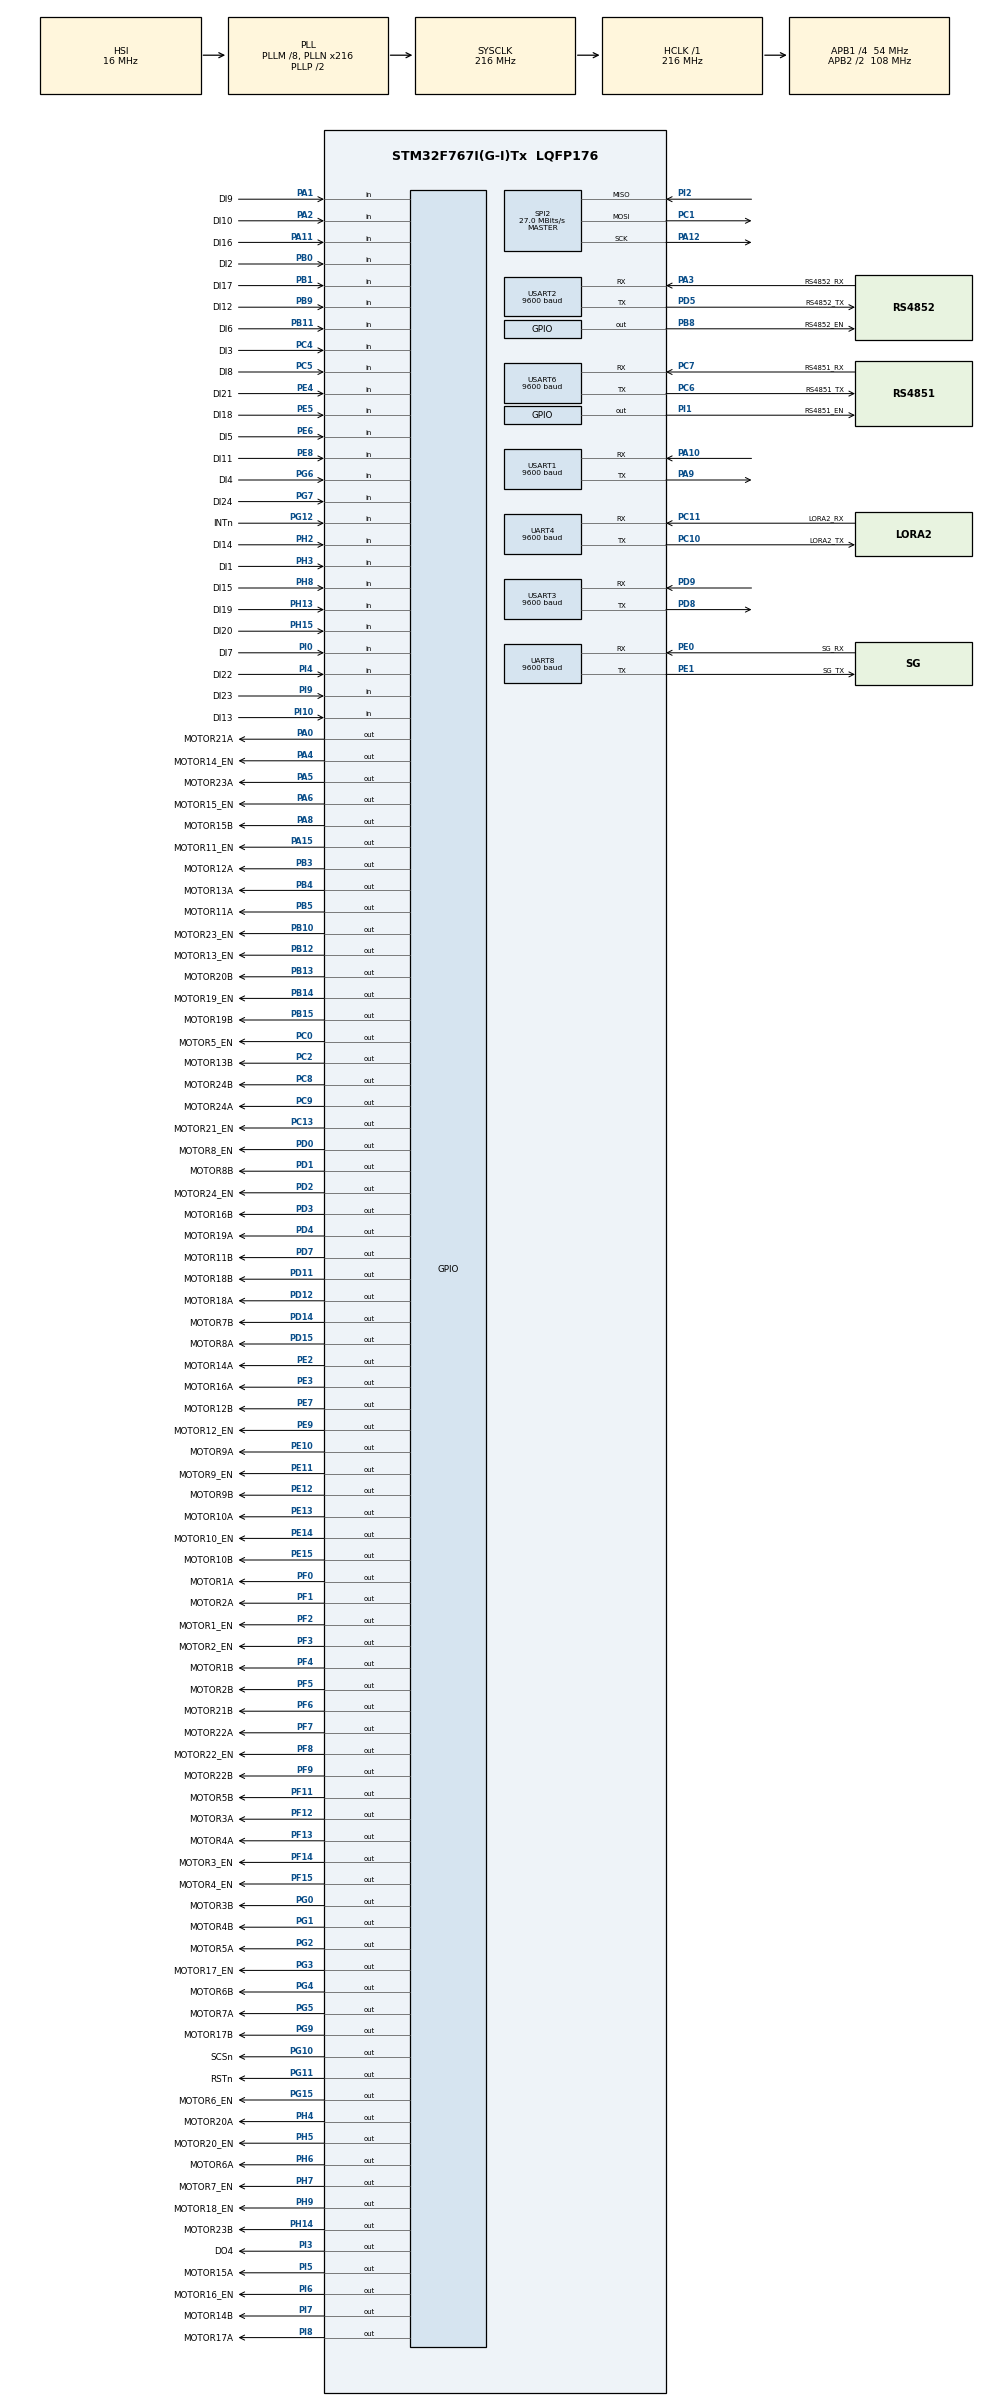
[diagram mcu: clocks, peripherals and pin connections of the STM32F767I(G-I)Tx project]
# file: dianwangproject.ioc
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Dma.Request0=USART6_RX
Dma.Request1=USART6_TX
Dma.Request10=USART3_TX
Dma.Request2=USART1_RX
Dma.Request3=USART1_TX
Dma.Request4=USART2_RX
Dma.Request5=USART2_TX
Dma.Request6=UART4_RX
Dma.Request7=UART4_TX
Dma.Request8=UART8_TX
Dma.Request9=USART3_RX
Dma.UART4_RX.6.Direction=DMA_PERIPH_TO_MEMORY
Dma.UART4_RX.6.FIFOMode=DMA_FIFOMODE_DISABLE
Dma.UART4_RX.6.Instance=DMA1_Stream2
Dma.UART4_RX.6.MemDataAlignment=DMA_MDATAALIGN_BYTE
Dma.UART4_RX.6.MemInc=DMA_MINC_ENABLE
Dma.UART4_RX.6.Mode=DMA_NORMAL
Dma.UART4_RX.6.PeriphDataAlignment=DMA_PDATAALIGN_BYTE
Dma.UART4_RX.6.PeriphInc=DMA_PINC_DISABLE
Dma.UART4_RX.6.Priority=DMA_PRIORITY_LOW
Dma.UART4_TX.7.Direction=DMA_MEMORY_TO_PERIPH
Dma.UART4_TX.7.FIFOMode=DMA_FIFOMODE_DISABLE
Dma.UART4_TX.7.Instance=DMA1_Stream4
Dma.UART4_TX.7.MemDataAlignment=DMA_MDATAALIGN_BYTE
Dma.UART4_TX.7.MemInc=DMA_MINC_ENABLE
Dma.UART4_TX.7.Mode=DMA_NORMAL
Dma.UART4_TX.7.PeriphDataAlignment=DMA_PDATAALIGN_BYTE
Dma.UART4_TX.7.PeriphInc=DMA_PINC_DISABLE
Dma.UART4_TX.7.Priority=DMA_PRIORITY_LOW
Dma.UART8_TX.8.Direction=DMA_MEMORY_TO_PERIPH
Dma.UART8_TX.8.FIFOMode=DMA_FIFOMODE_DISABLE
Dma.UART8_TX.8.Instance=DMA1_Stream0
Dma.UART8_TX.8.MemDataAlignment=DMA_MDATAALIGN_BYTE
Dma.UART8_TX.8.MemInc=DMA_MINC_ENABLE
Dma.UART8_TX.8.Mode=DMA_NORMAL
Dma.UART8_TX.8.PeriphDataAlignment=DMA_PDATAALIGN_BYTE
Dma.UART8_TX.8.PeriphInc=DMA_PINC_DISABLE
Dma.UART8_TX.8.Priority=DMA_PRIORITY_LOW
Dma.USART1_RX.2.Direction=DMA_PERIPH_TO_MEMORY
Dma.USART1_RX.2.FIFOMode=DMA_FIFOMODE_DISABLE
Dma.USART1_RX.2.Instance=DMA2_Stream2
Dma.USART1_RX.2.MemDataAlignment=DMA_MDATAALIGN_BYTE
Dma.USART1_RX.2.MemInc=DMA_MINC_ENABLE
Dma.USART1_RX.2.Mode=DMA_NORMAL
Dma.USART1_RX.2.PeriphDataAlignment=DMA_PDATAALIGN_BYTE
Dma.USART1_RX.2.PeriphInc=DMA_PINC_DISABLE
Dma.USART1_RX.2.Priority=DMA_PRIORITY_LOW
Dma.USART1_TX.3.Direction=DMA_MEMORY_TO_PERIPH
Dma.USART1_TX.3.FIFOMode=DMA_FIFOMODE_DISABLE
Dma.USART1_TX.3.Instance=DMA2_Stream7
Dma.USART1_TX.3.MemDataAlignment=DMA_MDATAALIGN_BYTE
Dma.USART1_TX.3.MemInc=DMA_MINC_ENABLE
Dma.USART1_TX.3.Mode=DMA_NORMAL
Dma.USART1_TX.3.PeriphDataAlignment=DMA_PDATAALIGN_BYTE
Dma.USART1_TX.3.PeriphInc=DMA_PINC_DISABLE
Dma.USART1_TX.3.Priority=DMA_PRIORITY_LOW
Dma.USART2_RX.4.Direction=DMA_PERIPH_TO_MEMORY
Dma.USART2_RX.4.FIFOMode=DMA_FIFOMODE_DISABLE
Dma.USART2_RX.4.Instance=DMA1_Stream5
Dma.USART2_RX.4.MemDataAlignment=DMA_MDATAALIGN_BYTE
Dma.USART2_RX.4.MemInc=DMA_MINC_ENABLE
Dma.USART2_RX.4.Mode=DMA_NORMAL
Dma.USART2_RX.4.PeriphDataAlignment=DMA_PDATAALIGN_BYTE
Dma.USART2_RX.4.PeriphInc=DMA_PINC_DISABLE
Dma.USART2_RX.4.Priority=DMA_PRIORITY_LOW
Dma.USART2_TX.5.Direction=DMA_MEMORY_TO_PERIPH
Dma.USART2_TX.5.FIFOMode=DMA_FIFOMODE_DISABLE
Dma.USART2_TX.5.Instance=DMA1_Stream6
Dma.USART2_TX.5.MemDataAlignment=DMA_MDATAALIGN_BYTE
Dma.USART2_TX.5.MemInc=DMA_MINC_ENABLE
Dma.USART2_TX.5.Mode=DMA_NORMAL
Dma.USART2_TX.5.PeriphDataAlignment=DMA_PDATAALIGN_BYTE
Dma.USART2_TX.5.PeriphInc=DMA_PINC_DISABLE
Dma.USART2_TX.5.Priority=DMA_PRIORITY_LOW
Dma.USART3_RX.9.Direction=DMA_PERIPH_TO_MEMORY
Dma.USART3_RX.9.FIFOMode=DMA_FIFOMODE_DISABLE
Dma.USART3_RX.9.Instance=DMA1_Stream1
Dma.USART3_RX.9.MemDataAlignment=DMA_MDATAALIGN_BYTE
Dma.USART3_RX.9.MemInc=DMA_MINC_ENABLE
Dma.USART3_RX.9.Mode=DMA_NORMAL
Dma.USART3_RX.9.PeriphDataAlignment=DMA_PDATAALIGN_BYTE
Dma.USART3_RX.9.PeriphInc=DMA_PINC_DISABLE
Dma.USART3_RX.9.Priority=DMA_PRIORITY_LOW
Dma.USART3_TX.10.Direction=DMA_MEMORY_TO_PERIPH
Dma.USART3_TX.10.FIFOMode=DMA_FIFOMODE_DISABLE
Dma.USART3_TX.10.Instance=DMA1_Stream3
Dma.USART3_TX.10.MemDataAlignment=DMA_MDATAALIGN_BYTE
Dma.USART3_TX.10.MemInc=DMA_MINC_ENABLE
Dma.USART3_TX.10.Mode=DMA_NORMAL
Dma.USART3_TX.10.PeriphDataAlignment=DMA_PDATAALIGN_BYTE
Dma.USART3_TX.10.PeriphInc=DMA_PINC_DISABLE
Dma.USART3_TX.10.Priority=DMA_PRIORITY_LOW
Dma.USART6_RX.0.Direction=DMA_PERIPH_TO_MEMORY
Dma.USART6_RX.0.FIFOMode=DMA_FIFOMODE_DISABLE
Dma.USART6_RX.0.Instance=DMA2_Stream1
Dma.USART6_RX.0.MemDataAlignment=DMA_MDATAALIGN_BYTE
Dma.USART6_RX.0.MemInc=DMA_MINC_ENABLE
Dma.USART6_RX.0.Mode=DMA_NORMAL
Dma.USART6_RX.0.PeriphDataAlignment=DMA_PDATAALIGN_BYTE
Dma.USART6_RX.0.PeriphInc=DMA_PINC_DISABLE
Dma.USART6_RX.0.Priority=DMA_PRIORITY_VERY_HIGH
Dma.USART6_TX.1.Direction=DMA_MEMORY_TO_PERIPH
Dma.USART6_TX.1.FIFOMode=DMA_FIFOMODE_DISABLE
Dma.USART6_TX.1.Instance=DMA2_Stream6
Dma.USART6_TX.1.MemDataAlignment=DMA_MDATAALIGN_BYTE
Dma.USART6_TX.1.MemInc=DMA_MINC_ENABLE
Dma.USART6_TX.1.Mode=DMA_NORMAL
Dma.USART6_TX.1.PeriphDataAlignment=DMA_PDATAALIGN_BYTE
Dma.USART6_TX.1.PeriphInc=DMA_PINC_DISABLE
Dma.USART6_TX.1.Priority=DMA_PRIORITY_VERY_HIGH
Mcu.Family=STM32F7
Mcu.Name=STM32F767I(G-I)Tx
Mcu.Package=LQFP176
NVIC.DMA1_Stream0_IRQn=true\:0\:0\:false\:false\:true\:false\:true\:true
NVIC.DMA1_Stream1_IRQn=true\:0\:0\:false\:false\:true\:false\:true\:true
NVIC.DMA1_Stream2_IRQn=true\:0\:0\:false\:false\:true\:false\:true\:true
NVIC.DMA1_Stream3_IRQn=true\:0\:0\:false\:false\:true\:false\:true\:true
NVIC.DMA1_Stream4_IRQn=true\:0\:0\:false\:false\:true\:false\:true\:true
NVIC.DMA1_Stream5_IRQn=true\:0\:0\:false\:false\:true\:false\:true\:true
NVIC.DMA1_Stream6_IRQn=true\:0\:0\:false\:false\:true\:false\:true\:true
NVIC.DMA2_Stream1_IRQn=true\:0\:0\:false\:false\:true\:false\:true\:true
NVIC.DMA2_Stream2_IRQn=true\:0\:0\:false\:false\:true\:false\:true\:true
NVIC.DMA2_Stream6_IRQn=true\:0\:0\:false\:false\:true\:false\:true\:true
NVIC.DMA2_Stream7_IRQn=true\:0\:0\:false\:false\:true\:false\:true\:true
NVIC.PriorityGroup=NVIC_PRIORITYGROUP_4
NVIC.TIM2_IRQn=true\:0\:0\:false\:false\:true\:true\:true\:true
NVIC.TIM3_IRQn=true\:0\:0\:false\:false\:true\:true\:true\:true
NVIC.UART4_IRQn=true\:0\:0\:false\:false\:true\:true\:true\:true
NVIC.UART8_IRQn=true\:0\:0\:false\:false\:true\:true\:true\:true
NVIC.USART1_IRQn=true\:0\:0\:false\:false\:true\:true\:true\:true
NVIC.USART2_IRQn=true\:0\:0\:false\:false\:true\:true\:true\:true
NVIC.USART3_IRQn=true\:0\:0\:false\:false\:true\:true\:true\:true
NVIC.USART6_IRQn=true\:0\:0\:false\:false\:true\:true\:true\:true
PA0/WKUP.GPIO_Label=MOTOR21A
PA0/WKUP.GPIO_Speed=GPIO_SPEED_FREQ_HIGH
PA0/WKUP.Signal=GPIO_Output
PA1.GPIO_Label=DI9
PA1.GPIO_PuPd=GPIO_PULLUP
PA1.Signal=GPIO_Input
PA10.Mode=Asynchronous
PA10.Signal=USART1_RX
PA11.GPIO_Label=DI16
PA11.GPIO_PuPd=GPIO_PULLUP
PA11.Signal=GPIO_Input
PA12.Mode=Full_Duplex_Master
PA12.Signal=SPI2_SCK
PA13.Mode=Serial_Wire
PA13.Signal=SYS_JTMS-SWDIO
PA14.Mode=Serial_Wire
PA14.Signal=SYS_JTCK-SWCLK
PA15.GPIO_Label=MOTOR11_EN
PA15.GPIO_Speed=GPIO_SPEED_FREQ_HIGH
PA15.PinState=GPIO_PIN_SET
PA15.Signal=GPIO_Output
PA2.GPIO_Label=DI10
PA2.GPIO_PuPd=GPIO_PULLUP
PA2.Signal=GPIO_Input
PA3.GPIO_Label=RS4852_RX
PA3.Mode=Asynchronous
PA3.Signal=USART2_RX
PA4.GPIO_Label=MOTOR14_EN
PA4.GPIO_Speed=GPIO_SPEED_FREQ_HIGH
PA4.Signal=GPIO_Output
PA5.GPIO_Label=MOTOR23A
PA5.GPIO_Speed=GPIO_SPEED_FREQ_HIGH
PA5.Signal=GPIO_Output
PA6.GPIO_Label=MOTOR15_EN
PA6.GPIO_Speed=GPIO_SPEED_FREQ_HIGH
PA6.Signal=GPIO_Output
PA8.GPIO_Label=MOTOR15B
PA8.GPIO_Speed=GPIO_SPEED_FREQ_HIGH
PA8.Signal=GPIO_Output
PA9.Mode=Asynchronous
PA9.Signal=USART1_TX
PB0.GPIO_Label=DI2
PB0.GPIO_PuPd=GPIO_PULLUP
PB0.Signal=GPIO_Input
PB1.GPIO_Label=DI17
PB1.GPIO_PuPd=GPIO_PULLUP
PB1.Signal=GPIO_Input
PB10.GPIO_Label=MOTOR23_EN
PB10.GPIO_Speed=GPIO_SPEED_FREQ_HIGH
PB10.Signal=GPIO_Output
PB11.GPIO_Label=DI6
PB11.GPIO_PuPd=GPIO_PULLUP
PB11.Signal=GPIO_Input
PB12.GPIO_Label=MOTOR13_EN
PB12.GPIO_Speed=GPIO_SPEED_FREQ_HIGH
PB12.Signal=GPIO_Output
PB13.GPIO_Label=MOTOR20B
PB13.GPIO_Speed=GPIO_SPEED_FREQ_HIGH
PB13.Signal=GPIO_Output
PB14.GPIO_Label=MOTOR19_EN
PB14.GPIO_Speed=GPIO_SPEED_FREQ_HIGH
PB14.Signal=GPIO_Output
PB15.GPIO_Label=MOTOR19B
PB15.GPIO_Speed=GPIO_SPEED_FREQ_HIGH
PB15.Signal=GPIO_Output
PB3.GPIO_Label=MOTOR12A
PB3.GPIO_Speed=GPIO_SPEED_FREQ_HIGH
PB3.Signal=GPIO_Output
PB4.GPIO_Label=MOTOR13A
PB4.GPIO_Speed=GPIO_SPEED_FREQ_HIGH
PB4.Signal=GPIO_Output
PB5.GPIO_Label=MOTOR11A
PB5.GPIO_Speed=GPIO_SPEED_FREQ_HIGH
PB5.PinState=GPIO_PIN_SET
PB5.Signal=GPIO_Output
PB8.GPIO_Label=RS4852_EN
PB8.GPIO_Speed=GPIO_SPEED_FREQ_HIGH
PB8.PinState=GPIO_PIN_RESET
PB8.Signal=GPIO_Output
PB9.GPIO_Label=DI12
PB9.GPIO_PuPd=GPIO_PULLUP
PB9.Signal=GPIO_Input
PC0.GPIO_Label=MOTOR5_EN
PC0.GPIO_Speed=GPIO_SPEED_FREQ_HIGH
PC0.Signal=GPIO_Output
PC1.Mode=Full_Duplex_Master
PC1.Signal=SPI2_MOSI
PC10.GPIO_Label=LORA2_TX
PC10.Mode=Asynchronous
PC10.Signal=UART4_TX
PC11.GPIO_Label=LORA2_RX
PC11.Mode=Asynchronous
PC11.Signal=UART4_RX
PC13.GPIO_Label=MOTOR21_EN
PC13.Signal=GPIO_Output
PC14/OSC32_IN.Mode=LSE-External-Oscillator
PC14/OSC32_IN.Signal=RCC_OSC32_IN
PC15/OSC32_OUT.Mode=LSE-External-Oscillator
PC15/OSC32_OUT.Signal=RCC_OSC32_OUT
PC2.GPIO_Label=MOTOR13B
PC2.GPIO_Speed=GPIO_SPEED_FREQ_HIGH
PC2.Signal=GPIO_Output
PC4.GPIO_Label=DI3
PC4.GPIO_PuPd=GPIO_PULLUP
PC4.Signal=GPIO_Input
PC5.GPIO_Label=DI8
PC5.GPIO_PuPd=GPIO_PULLUP
PC5.Signal=GPIO_Input
PC6.GPIO_Label=RS4851_TX
PC6.Mode=Asynchronous
PC6.Signal=USART6_TX
PC7.GPIO_Label=RS4851_RX
PC7.Mode=Asynchronous
PC7.Signal=USART6_RX
PC8.GPIO_Label=MOTOR24B
PC8.GPIO_Speed=GPIO_SPEED_FREQ_HIGH
PC8.Signal=GPIO_Output
PC9.GPIO_Label=MOTOR24A
PC9.GPIO_Speed=GPIO_SPEED_FREQ_HIGH
PC9.Signal=GPIO_Output
PD0.GPIO_Label=MOTOR8_EN
PD0.GPIO_Speed=GPIO_SPEED_FREQ_HIGH
PD0.Signal=GPIO_Output
PD1.GPIO_Label=MOTOR8B
PD1.GPIO_Speed=GPIO_SPEED_FREQ_HIGH
PD1.Signal=GPIO_Output
PD11.GPIO_Label=MOTOR18B
PD11.GPIO_Speed=GPIO_SPEED_FREQ_HIGH
PD11.Signal=GPIO_Output
PD12.GPIO_Label=MOTOR18A
PD12.GPIO_Speed=GPIO_SPEED_FREQ_HIGH
PD12.PinState=GPIO_PIN_SET
PD12.Signal=GPIO_Output
PD14.GPIO_Label=MOTOR7B
PD14.GPIO_Speed=GPIO_SPEED_FREQ_HIGH
PD14.Signal=GPIO_Output
PD15.GPIO_Label=MOTOR8A
PD15.GPIO_Speed=GPIO_SPEED_FREQ_HIGH
PD15.Signal=GPIO_Output
PD2.GPIO_Label=MOTOR24_EN
PD2.GPIO_Speed=GPIO_SPEED_FREQ_HIGH
PD2.Signal=GPIO_Output
PD3.GPIO_Label=MOTOR16B
PD3.GPIO_Speed=GPIO_SPEED_FREQ_HIGH
PD3.Signal=GPIO_Output
PD4.GPIO_Label=MOTOR19A
PD4.GPIO_Speed=GPIO_SPEED_FREQ_HIGH
PD4.Signal=GPIO_Output
PD5.GPIO_Label=RS4852_TX
PD5.Mode=Asynchronous
PD5.Signal=USART2_TX
PD7.GPIO_Label=MOTOR11B
PD7.GPIO_Speed=GPIO_SPEED_FREQ_HIGH
PD7.PinState=GPIO_PIN_SET
PD7.Signal=GPIO_Output
PD8.Mode=Asynchronous
PD8.Signal=USART3_TX
PD9.Mode=Asynchronous
PD9.Signal=USART3_RX
PE0.GPIO_Label=SG_RX
PE0.Mode=Asynchronous
PE0.Signal=UART8_RX
PE1.GPIO_Label=SG_TX
PE1.Mode=Asynchronous
PE1.Signal=UART8_TX
PE10.GPIO_Label=MOTOR9A
PE10.GPIO_Speed=GPIO_SPEED_FREQ_HIGH
PE10.Signal=GPIO_Output
PE11.GPIO_Label=MOTOR9_EN
PE11.GPIO_Speed=GPIO_SPEED_FREQ_HIGH
PE11.Signal=GPIO_Output
PE12.GPIO_Label=MOTOR9B
PE12.GPIO_Speed=GPIO_SPEED_FREQ_HIGH
PE12.Signal=GPIO_Output
PE13.GPIO_Label=MOTOR10A
PE13.GPIO_Speed=GPIO_SPEED_FREQ_HIGH
PE13.Signal=GPIO_Output
PE14.GPIO_Label=MOTOR10_EN
PE14.GPIO_Speed=GPIO_SPEED_FREQ_HIGH
PE14.Signal=GPIO_Output
PE15.GPIO_Label=MOTOR10B
PE15.GPIO_Speed=GPIO_SPEED_FREQ_HIGH
PE15.Signal=GPIO_Output
PE2.GPIO_Label=MOTOR14A
PE2.GPIO_Speed=GPIO_SPEED_FREQ_HIGH
PE2.Signal=GPIO_Output
PE3.GPIO_Label=MOTOR16A
PE3.GPIO_Speed=GPIO_SPEED_FREQ_HIGH
PE3.Signal=GPIO_Output
PE4.GPIO_Label=DI21
PE4.GPIO_PuPd=GPIO_PULLUP
PE4.Signal=GPIO_Input
PE5.GPIO_Label=DI18
PE5.GPIO_PuPd=GPIO_PULLUP
PE5.Signal=GPIO_Input
PE6.GPIO_Label=DI5
PE6.GPIO_PuPd=GPIO_PULLUP
PE6.Signal=GPIO_Input
PE7.GPIO_Label=MOTOR12B
PE7.GPIO_Speed=GPIO_SPEED_FREQ_HIGH
PE7.PinState=GPIO_PIN_SET
PE7.Signal=GPIO_Output
PE8.GPIO_Label=DI11
PE8.GPIO_PuPd=GPIO_PULLUP
PE8.Signal=GPIO_Input
PE9.GPIO_Label=MOTOR12_EN
PE9.GPIO_Speed=GPIO_SPEED_FREQ_HIGH
PE9.PinState=GPIO_PIN_SET
PE9.Signal=GPIO_Output
PF0.GPIO_Label=MOTOR1A
PF0.GPIO_Speed=GPIO_SPEED_FREQ_HIGH
PF0.Signal=GPIO_Output
PF1.GPIO_Label=MOTOR2A
PF1.GPIO_Speed=GPIO_SPEED_FREQ_HIGH
PF1.Signal=GPIO_Output
PF11.GPIO_Label=MOTOR5B
PF11.GPIO_Speed=GPIO_SPEED_FREQ_HIGH
PF11.Signal=GPIO_Output
PF12.GPIO_Label=MOTOR3A
PF12.GPIO_Speed=GPIO_SPEED_FREQ_HIGH
PF12.Signal=GPIO_Output
PF13.GPIO_Label=MOTOR4A
PF13.GPIO_Speed=GPIO_SPEED_FREQ_HIGH
PF13.Signal=GPIO_Output
PF14.GPIO_Label=MOTOR3_EN
PF14.GPIO_Speed=GPIO_SPEED_FREQ_HIGH
PF14.Signal=GPIO_Output
PF15.GPIO_Label=MOTOR4_EN
PF15.GPIO_Speed=GPIO_SPEED_FREQ_HIGH
PF15.Signal=GPIO_Output
PF2.GPIO_Label=MOTOR1_EN
PF2.GPIO_Speed=GPIO_SPEED_FREQ_HIGH
PF2.Signal=GPIO_Output
PF3.GPIO_Label=MOTOR2_EN
PF3.GPIO_Speed=GPIO_SPEED_FREQ_HIGH
PF3.Signal=GPIO_Output
PF4.GPIO_Label=MOTOR1B
PF4.GPIO_Speed=GPIO_SPEED_FREQ_HIGH
PF4.Signal=GPIO_Output
PF5.GPIO_Label=MOTOR2B
PF5.GPIO_Speed=GPIO_SPEED_FREQ_HIGH
PF5.Signal=GPIO_Output
PF6.GPIO_Label=MOTOR21B
PF6.GPIO_Speed=GPIO_SPEED_FREQ_HIGH
PF6.Signal=GPIO_Output
PF7.GPIO_Label=MOTOR22A
PF7.GPIO_Speed=GPIO_SPEED_FREQ_HIGH
PF7.Signal=GPIO_Output
PF8.GPIO_Label=MOTOR22_EN
PF8.GPIO_Speed=GPIO_SPEED_FREQ_HIGH
PF8.Signal=GPIO_Output
PF9.GPIO_Label=MOTOR22B
PF9.GPIO_Speed=GPIO_SPEED_FREQ_HIGH
PF9.Signal=GPIO_Output
PG0.GPIO_Label=MOTOR3B
PG0.GPIO_Speed=GPIO_SPEED_FREQ_HIGH
PG0.Signal=GPIO_Output
PG1.GPIO_Label=MOTOR4B
PG1.GPIO_Speed=GPIO_SPEED_FREQ_HIGH
PG1.Signal=GPIO_Output
PG10.GPIO_Label=SCSn
PG10.GPIO_ModeDefaultOutputPP=GPIO_MODE_OUTPUT_OD
PG10.GPIO_PuPd=GPIO_PULLUP
PG10.GPIO_Speed=GPIO_SPEED_FREQ_HIGH
PG10.PinState=GPIO_PIN_SET
PG10.Signal=GPIO_Output
PG11.GPIO_Label=RSTn
PG11.GPIO_ModeDefaultOutputPP=GPIO_MODE_OUTPUT_OD
PG11.GPIO_PuPd=GPIO_PULLUP
PG11.GPIO_Speed=GPIO_SPEED_FREQ_HIGH
PG11.PinState=GPIO_PIN_SET
PG11.Signal=GPIO_Output
PG12.GPIO_Label=INTn
PG12.Signal=GPIO_Input
PG15.GPIO_Label=MOTOR6_EN
PG15.GPIO_Speed=GPIO_SPEED_FREQ_HIGH
PG15.Signal=GPIO_Output
PG2.GPIO_Label=MOTOR5A
PG2.GPIO_Speed=GPIO_SPEED_FREQ_HIGH
PG2.Signal=GPIO_Output
PG3.GPIO_Label=MOTOR17_EN
PG3.GPIO_Speed=GPIO_SPEED_FREQ_HIGH
PG3.Signal=GPIO_Output
PG4.GPIO_Label=MOTOR6B
PG4.GPIO_Speed=GPIO_SPEED_FREQ_HIGH
PG4.Signal=GPIO_Output
PG5.GPIO_Label=MOTOR7A
PG5.GPIO_Speed=GPIO_SPEED_FREQ_HIGH
PG5.Signal=GPIO_Output
PG6.GPIO_Label=DI4
PG6.GPIO_PuPd=GPIO_PULLUP
PG6.Signal=GPIO_Input
PG7.GPIO_Label=DI24
PG7.GPIO_PuPd=GPIO_PULLUP
PG7.Signal=GPIO_Input
PG9.GPIO_Label=MOTOR17B
PG9.GPIO_Speed=GPIO_SPEED_FREQ_HIGH
PG9.Signal=GPIO_Output
PH0/OSC_IN.Mode=HSE-External-Oscillator
PH0/OSC_IN.Signal=RCC_OSC_IN
PH1/OSC_OUT.Mode=HSE-External-Oscillator
PH1/OSC_OUT.Signal=RCC_OSC_OUT
PH13.GPIO_Label=DI19
PH13.GPIO_PuPd=GPIO_PULLUP
PH13.Signal=GPIO_Input
PH14.GPIO_Label=MOTOR23B
PH14.GPIO_Speed=GPIO_SPEED_FREQ_HIGH
PH14.Signal=GPIO_Output
PH15.GPIO_Label=DI20
PH15.GPIO_PuPd=GPIO_PULLUP
PH15.Signal=GPIO_Input
PH2.GPIO_Label=DI14
PH2.GPIO_PuPd=GPIO_PULLUP
PH2.Signal=GPIO_Input
PH3.GPIO_Label=DI1
PH3.GPIO_PuPd=GPIO_PULLUP
PH3.Signal=GPIO_Input
PH4.GPIO_Label=MOTOR20A
PH4.GPIO_Speed=GPIO_SPEED_FREQ_HIGH
PH4.Signal=GPIO_Output
PH5.GPIO_Label=MOTOR20_EN
PH5.GPIO_Speed=GPIO_SPEED_FREQ_HIGH
PH5.Signal=GPIO_Output
PH6.GPIO_Label=MOTOR6A
PH6.GPIO_Speed=GPIO_SPEED_FREQ_HIGH
PH6.Signal=GPIO_Output
PH7.GPIO_Label=MOTOR7_EN
PH7.GPIO_Speed=GPIO_SPEED_FREQ_HIGH
PH7.Signal=GPIO_Output
PH8.GPIO_Label=DI15
PH8.GPIO_PuPd=GPIO_PULLUP
PH8.Signal=GPIO_Input
PH9.GPIO_Label=MOTOR18_EN
PH9.GPIO_Speed=GPIO_SPEED_FREQ_HIGH
PH9.Signal=GPIO_Output
PI0.GPIO_Label=DI7
PI0.GPIO_PuPd=GPIO_PULLUP
PI0.Signal=GPIO_Input
PI1.GPIO_Label=RS4851_EN
PI1.Signal=GPIO_Output
PI10.GPIO_Label=DI13
PI10.GPIO_PuPd=GPIO_PULLUP
PI10.Signal=GPIO_Input
PI2.Mode=Full_Duplex_Master
PI2.Signal=SPI2_MISO
PI3.GPIO_Label=DO4
PI3.Signal=GPIO_Output
PI4.GPIO_Label=DI22
PI4.GPIO_PuPd=GPIO_PULLUP
PI4.Signal=GPIO_Input
PI5.GPIO_Label=MOTOR15A
PI5.GPIO_Speed=GPIO_SPEED_FREQ_HIGH
PI5.Signal=GPIO_Output
PI6.GPIO_Label=MOTOR16_EN
PI6.GPIO_Speed=GPIO_SPEED_FREQ_HIGH
PI6.Signal=GPIO_Output
PI7.GPIO_Label=MOTOR14B
PI7.GPIO_Speed=GPIO_SPEED_FREQ_HIGH
PI7.Signal=GPIO_Output
PI8.GPIO_Label=MOTOR17A
PI8.Signal=GPIO_Output
PI9.GPIO_Label=DI23
PI9.GPIO_PuPd=GPIO_PULLUP
PI9.Signal=GPIO_Input
ProjectManager.HeapSize=0x200
ProjectManager.StackSize=0x400
ProjectManager.TargetToolchain=MDK-ARM V5.32
RCC.AHBFreq_Value=216000000
RCC.APB1CLKDivider=RCC_HCLK_DIV4
RCC.APB1Freq_Value=54000000
RCC.APB1TimFreq_Value=108000000
RCC.APB2CLKDivider=RCC_HCLK_DIV2
RCC.APB2Freq_Value=108000000
RCC.APB2TimFreq_Value=216000000
RCC.CortexFreq_Value=216000000
RCC.HCLKFreq_Value=216000000
RCC.HSE_VALUE=25000000
RCC.HSI_VALUE=16000000
RCC.PLLM=8
RCC.PLLN=216
RCC.SYSCLKFreq_VALUE=216000000
RCC.SYSCLKSource=RCC_SYSCLKSOURCE_PLLCLK
RCC.USBFreq_Value=216000000
RCC.VCOOutputFreq_Value=432000000
SPI2.CalculateBaudRate=27.0 MBits/s
SPI2.DataSize=SPI_DATASIZE_8BIT
SPI2.Direction=SPI_DIRECTION_2LINES
SPI2.Mode=SPI_MODE_MASTER
SPI2.VirtualType=VM_MASTER
TIM2.AutoReloadPreload=TIM_AUTORELOAD_PRELOAD_ENABLE
TIM2.Period=1000-1
TIM2.Prescaler=216-1
TIM3.Period=1000-1
TIM3.Prescaler=21600-1
UART4.BaudRate=9600
UART8.BaudRate=9600
USART1.BaudRate=9600
USART1.VirtualMode-Asynchronous=VM_ASYNC
USART2.BaudRate=9600
USART2.VirtualMode-Asynchronous=VM_ASYNC
USART3.BaudRate=9600
USART3.VirtualMode-Asynchronous=VM_ASYNC
USART6.BaudRate=9600
USART6.VirtualMode-Asynchronous=VM_ASYNC
VP_TIM2_VS_ClockSourceINT.Mode=Internal
VP_TIM3_VS_ClockSourceINT.Mode=Internal
board=custom

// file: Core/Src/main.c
/* USER CODE BEGIN Header */
/**
  ******************************************************************************
  * @file           : main.c
  * @brief          : Main program body
  ******************************************************************************
  * @attention
  *
  * Copyright (c) 2025 STMicroelectronics.
  * All rights reserved.
  *
  * This software is licensed under terms that can be found in the LICENSE file
  * in the root directory of this software component.
  * If no LICENSE file comes with this software, it is provided AS-IS.
  *
  ******************************************************************************
  */
/* USER CODE END Header */
#include "main.h"
#include "dma.h"
#include "spi.h"
#include "tim.h"
#include "usart.h"
#include "gpio.h"

/* USER CODE BEGIN Includes */

#include "string.h"
#include <stdbool.h>
#include "user_main.h"

#include <stdio.h>
#include <stdint.h>
#include "wizchip_conf.h"
#include "wiz_interface.h"
#include "loopback.h"
/* USER CODE END Includes */

void SystemClock_Config(void);

/* USER CODE BEGIN 0 */
//舵机指令
uint8_t sg_reset[]={0XFA,0X00,0XFB,0XFB,0XFE};
uint8_t sg_cotdata[]={0XFA,0X00,0X00,0X00,0XFE};

//控制指令
uint8_t HeartPulse[] = {0x06,0xAA,0x53, 0x54,0x4D,0x33,0x32,0x46,0x31,0x30,0x33,0x63,0x63};//心跳包

uint8_t SMLimitCmd[]={0x0B,0x03,0x03,0x0A,0x00,0x02,0xE4,0xE7};//读步步进限位
uint8_t SMPositionCmd[]={0x09,0x03,0x03,0x10,0x00,0x02,0xC4,0xC2};//读步进位置
uint8_t GPSCmd[]={0x31,0x03,0x00,0xCF,0x00,0x06,0xF0,0x07};//读GPS数据
uint8_t HeightCmd[]={0x16,0x03,0x00,0x04,0x00,0x01,0xC6,0xEC};//读激光测距传感器（平台距地面高度）
uint8_t LiftCmd[]={0x18,0x03,0x02,0x01,0x00,0x01,0xD6,0x7B};//读TOF测距传感器（升降台)
uint8_t BoPiCmd[]={0xA2,0x03,0xA2,0x00,0x00,0x0D,0xBF,0x24};//剥皮器读指令
uint8_t SGCmd[]={0xFA,0x00,0x00,0x5A,0xFE};//舵机指令
uint8_t Lora2Set[]={0xC0,0x00, 0x65, 0x18, 0x49, 0x1c};//剥皮器读指令

uint8_t LcaCmd[] = {0x04,0x03,0x00,0x00,0x00,0x03,0x05,0x9E};//读平台角度
//uint8_t LcaCmd[] = {0x04,0x03,0x00,0x02,0x00,0x07,0xA5,0x9D};	//读平台角度:RPY+温度
//uint8_t HeightCmd[]={0x16,0x03,0x00,0x04,0x00,0x01,0xC6,0xEC};//读激光测距传感器（平台高度）
uint8_t Height20Cmd[] = {0x20,0x03,0x00,0x34,0x00,0x01,0xC3,0x75};	//读平台距挂钩高度
uint8_t Height21Cmd[] = {0x21,0x03,0x00,0x34,0x00,0x01,0xC2,0xA4};	//读平台距挂钩高度
uint8_t Height22Cmd[] = {0x22,0x03,0x00,0x34,0x00,0x01,0xC2,0x97};	//读平台距主线高度
uint8_t Height23Cmd[] = {0x23,0x03,0x00,0x34,0x00,0x01,0xC3,0x46};	//读平台距主线高度
uint8_t PressureSensorCmd[]={0x30,0x03,0x00,0x00,0x00,0x01,0x80,0x2B};	//读压线钳压力传感器
uint8_t TakePressureSensorCmd[]={0x31,0x03,0x00,0x00,0x00,0x02,0xC1,0xFB};	//读送给器压力传感器
uint8_t TakePressureSensorSetZeroCmd[] = {0x31,0x06,0x00,0x35,0x00,0x05,0x5C,0x37};//送给器压力传感器校准零点

uint8_t Lora1_Redata[50];//lora1接受数组缓冲区
uint8_t Lora2_Redata[50];//lora2接受数组缓冲区
uint8_t RS4851_Redata[80];//RS4851接受数组缓冲区
uint8_t RS4852_Redata[80];//RS4852接受数组缓冲区
uint8_t Usart1_Redata[36];//ttl串口1接受数据缓冲区
uint8_t Usart3_Redata[36];//ttl串口1接受数据缓冲区

//for RS4852 handler
extern uint8_t recv_cmd[50];
extern uint16_t recv_length;
extern uint8_t isControlCmdReceived;

uint8_t AngleSV[]={0xFA,0x00,0xFD,
		                 0x00,0x00,0x00,0x78,
										 0x78,0x00,0x00,0x00,
										 0x5A,0x30,0x3C,0x00,
										 0x00,0x00,0x00,0x00,
										 0x00,0x00,0x00,0x00,
	                   0xFE};
//Lora 发送数据包

unsigned char Send_data[LoraDataLength];

//stm32通讯方式
uint8_t CommMode;//0-lora  1-wifi

extern uint16_t uart6_rx_size;

extern uint16_t local_port;
extern uint8_t ethernet_buf[ETHERNET_BUF_MAX_SIZE];

uint8_t  tcp_buff[512];  //tcp接受数组
uint16_t tcp_len;
uint8_t  TCP_Recved=0;   //tcp接受标志位

/* USER CODE END 0 */

int main(void)
{

  /* MCU Configuration--------------------------------------------------------*/

  /* Reset of all peripherals, Initializes the Flash interface and the Systick. */
  HAL_Init();

  /* Configure the system clock */
  SystemClock_Config();

  /* Initialize all configured peripherals */
  MX_DMA_Init();
  MX_GPIO_Init();

  MX_USART6_UART_Init();
  MX_USART1_UART_Init();
  MX_UART8_Init();
  MX_USART2_UART_Init();
  MX_UART4_Init();
  MX_USART3_UART_Init();
  MX_TIM2_Init();
  MX_SPI2_Init();
  MX_TIM3_Init();
  /* USER CODE BEGIN 2 */

	SG_init();		//舵机初始化
	HAL_TIM_Base_Start_IT(&htim3);//开启定时器

  Send_data[0] =0x06;
  Send_data[1] =0xFF;										//Lora:0x00; Wifi:0x01
	for(int i = 2;i<LoraDataLength;i++)
		 Send_data[i] = 0x00;

	HAL_UARTEx_ReceiveToIdle_IT(&huart1,Usart1_Redata,sizeof(Usart1_Redata));
	HAL_UARTEx_ReceiveToIdle_IT(&huart6,RS4851_Redata,sizeof(RS4851_Redata));
	HAL_UARTEx_ReceiveToIdle_IT(&huart2,RS4852_Redata,sizeof(RS4852_Redata));
	HAL_UARTEx_ReceiveToIdle_DMA(&huart3,Lora1_Redata,sizeof(Lora1_Redata));
	HAL_UARTEx_ReceiveToIdle_IT(&huart4,Lora2_Redata,sizeof(Lora2_Redata));
  __HAL_DMA_DISABLE_IT(&hdma_usart3_rx,DMA_IT_HT);//关闭DMA接受过半中断

	wifi_init();
	CommMode = 0;

  /* USER CODE END 2 */

  /* Infinite loop */
  /* USER CODE BEGIN WHILE */
  while (1)
  {

//		Lora1_SendData(Height20Cmd, 8);  //LOAR1
//		HAL_Delay(1000);

//		Motor_Control(MOTOR1, 1);
//		HAL_Delay(1000);
//		Motor_Control(MOTOR1, 1);
//		HAL_Delay(1000);

		//loopback_tcps(SOCKET_ID, tcp_buff, local_port);
		do_tcp_server(SOCKET_ID, tcp_buff, local_port);

    /* USER CODE END WHILE */

  }
}

void SystemClock_Config(void)
{
  RCC_OscInitTypeDef RCC_OscInitStruct = {0};
  RCC_ClkInitTypeDef RCC_ClkInitStruct = {0};

  /** Configure LSE Drive Capability
  */
  HAL_PWR_EnableBkUpAccess();

  /** Configure the main internal regulator output voltage
  */
  __HAL_RCC_PWR_CLK_ENABLE();
  __HAL_PWR_VOLTAGESCALING_CONFIG(PWR_REGULATOR_VOLTAGE_SCALE1);

  /** Initializes the RCC Oscillators according to the specified parameters
  * in the RCC_OscInitTypeDef structure.
  */
  RCC_OscInitStruct.OscillatorType = RCC_OSCILLATORTYPE_HSI;
  RCC_OscInitStruct.HSIState = RCC_HSI_ON;
  RCC_OscInitStruct.HSICalibrationValue = RCC_HSICALIBRATION_DEFAULT;
  RCC_OscInitStruct.PLL.PLLState = RCC_PLL_ON;
  RCC_OscInitStruct.PLL.PLLSource = RCC_PLLSOURCE_HSI;
  RCC_OscInitStruct.PLL.PLLM = 8;
  RCC_OscInitStruct.PLL.PLLN = 216;
  RCC_OscInitStruct.PLL.PLLP = RCC_PLLP_DIV2;
  RCC_OscInitStruct.PLL.PLLQ = 2;
  RCC_OscInitStruct.PLL.PLLR = 2;
  if (HAL_RCC_OscConfig(&RCC_OscInitStruct) != HAL_OK)
  {
    Error_Handler();
  }

  /** Activate the Over-Drive mode
  */
  if (HAL_PWREx_EnableOverDrive() != HAL_OK)
  {
    Error_Handler();
  }

  /** Initializes the CPU, AHB and APB buses clocks
  */
  RCC_ClkInitStruct.ClockType = RCC_CLOCKTYPE_HCLK|RCC_CLOCKTYPE_SYSCLK
                              |RCC_CLOCKTYPE_PCLK1|RCC_CLOCKTYPE_PCLK2;
  RCC_ClkInitStruct.SYSCLKSource = RCC_SYSCLKSOURCE_PLLCLK;
  RCC_ClkInitStruct.AHBCLKDivider = RCC_SYSCLK_DIV1;
  RCC_ClkInitStruct.APB1CLKDivider = RCC_HCLK_DIV4;
  RCC_ClkInitStruct.APB2CLKDivider = RCC_HCLK_DIV2;

  if (HAL_RCC_ClockConfig(&RCC_ClkInitStruct, FLASH_LATENCY_7) != HAL_OK)
  {
    Error_Handler();
  }
}

void Error_Handler(void)
{
  __disable_irq();
  while (1)
  {
  }
}
